# LPC8N04 register map
File version: 0.1
CPU: CM0PLUS r0p0, little endian, no MPU, no FPU, 2 interrupt priority bits
Registers are 32-bit, read-write, no defined reset value unless marked. A register's access mark holds for its fields unless they carry their own. Offsets are from the block's base; [hi:lo] are bit positions.

## FLASH — Flash controller
Base 0x4003C000
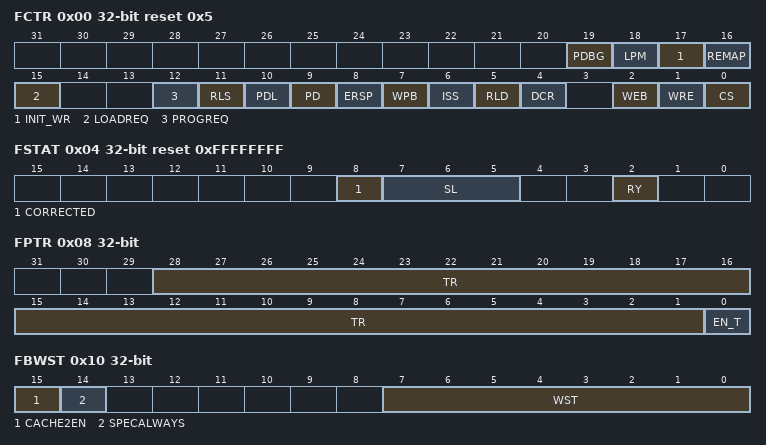
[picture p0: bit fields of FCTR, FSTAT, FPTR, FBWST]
0x00 FCTR reset 0x5 (reset mask 0x0) — Flash Control register
  [19] PDBG — When set, bandgap goes into powerdown mode.
  [18] LPM — When set, the memory goes into low power mode.
  [17] INIT_WR — Writing a ?1? to this field together with reset values for all other fields of the FCTR register starts write initialization. Once set, this bit is only cleared by a controller reset.
  [16] REMAP — When 1, address remapping is enabled
  [15] LOADREQ — When it is written with 1, a memory write operation is triggered. Always reads as 0.
  [12] PROGREQ — At 1 whenever the memory is busy doing program/erase
  [11] RLS — When 1, sector latches are read instead of the memory array.
  [10] PDL — When high, the page register is preset to all 1.
  [9] PD — When high, the memory is forced into power-down mode.
  [8] ERSP — If set, single page erase mode is enabled. The bit is automatically reset at the end of the erase
  [7] WPB — When 1, program/erase is enabled. When 0, read or write is selected, depending on bit WEB
  [6] ISS — When 1, the index sector is accessed instead of the main array. When 0, the MSB of the address bus determines index sector access.
  [5] RLD — When 1, the page register datalatches are read instead of the matrix. Row and sector address bits are not significant
  [4] DCR — When 1, DC Read mode is selected
  [2] WEB — When this bit is cleared, program/erase starts. It is automatically set to 1 at the end of the operation
  [1] WRE — When bit WPB=1, this bit selects between erase (WRE=0) and program (WRE=1). When WPB=0, it selects between read (WRE=0) and write (WRE=1).
  [0] CS — When 0, the device is in standby mode. CS must be 1 for proper operation.
0x04 FSTAT ro reset 0xFFFFFFFF (reset mask 0x0) — Flash status register
  [8] CORRECTED — ECC detected a correctable error
  [7:5] SL — Sector latches: bit 2=selected, 1=locked, 0=protected
  [2] RY — RY=1 whenever the flash is not busy reading, programming or erasing
0x08 FPTR — Flash program-time register
  [28:1] TR — Duration of the program/erase pulse, in timing reference clock cycles.
  [0] EN_T — When set, timer starts. It is automatically cleared when TR reaches 0.
0x10 FBWST — Flash wait state register
  [15] CACHE2EN — When caching is enabled: if this bit is 1, more than a word can be cached; otherwise only the last word read is kept in the cache. When caching is disabled or unavailable, this bit has no effect.
  [14] SPECALWAYS — Speculative reading: (0) single speculative reading; (1) always speculative reading
  [7:0] WST — number of wait states
0x1C FCRA — Flash program clock divider
  [11:0] FCRA — When 0, FCRA clock is stopped. Otherwise, its frequency is the timing reference clock frequency divided by (FCRA+1).
0x20 FMSSTART — Flash checksum start address register
  [16:0] STARTA — Start address for signature generation. The address is in units of memory words, not bytes. Bits 2:0 cannot be written and are forced to 000.
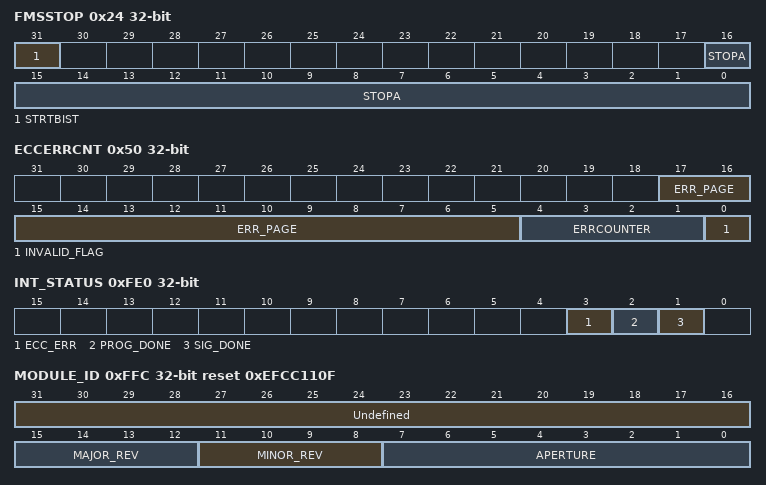
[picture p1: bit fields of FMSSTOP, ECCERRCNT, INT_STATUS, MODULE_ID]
0x24 FMSSTOP — Flash checksum stop address register
  [31] STRTBIST — When this bit is written to 1, signature generation starts. At the end of signature generation, this bit is automatically cleared.
  [16:0] STOPA — Stop address for signature generation (the word specified by STOPA is included in the address range). The address is in units of memory words, not bytes. Bits 2:0 cannot be written and are forced to 111.
0x28 FMS16 ro reset 0xFFFFFFFF (reset mask 0x0) — Flash parity signature register
  [15:0] FMS16 — After signature generation has run, this field contains the parity signature for the specified address range
0x2C FMSW0 ro reset 0xFFFFFFFF (reset mask 0x0) — Flash data signature register
  [31:0] FMSW0 — After signature generation has run, this field contains the data signature for the specified address range
0x50 ECCERRCNT ro — ECC status information
  [17:5] ERR_PAGE — page address of the last location containing an ECC (correctable or uncorrectable) error. Only significant if ERRCOUNTER or INVALID_FLAG are non-zero.
  [4:1] ERRCOUNTER — Incremented when an ECC correction occurs (saturates at 1111). Cleared by writing 1 into ECCRSTERRCNT.
  [0] INVALID_FLAG — Set when an uncorrectable ECC error occurs. Cleared by writing 1 into ECCRSTERRCNT
0x54 ECCRSTERRCNT — Invalid flag and error corrected counter reset
  [0] ECCRSTERRCNT — When set, it clears the ECCERRCNT register. Always reads as 0.
0xFD8 INT_CLR_ENABLE wo — Clear interrupt enable bits
  [31:0] CLR_ENABLE — When a CLR_ENABLE bit is written to 1, the corresponding INT_ENABLE bit is cleared.
0xFDC INT_SET_ENABLE wo — Set interrupt enable bits
  [31:0] SET_ENABLE — When a SET_ENABLE bit is written to 1, the corresponding INT_ENABLE bit is set, unless it is a reserved bit.
0xFE0 INT_STATUS ro — Interrupt status bits
  [3] ECC_ERR — This status bit is set if, during a memory read operation (either a user-requested read, or a speculative read, or reads performed during initialization or during signature generation) a correctable or uncorrectable error is detected by ECC decoding logic.
  [2] PROG_DONE — This status bit is set at the end of a high-voltage operation (burn, erase, combined erase+program)
  [1] SIG_DONE — This status bit is set at the end of signature computation
0xFE4 INT_ENABLE wo — Interrupt enable bits
  [31:0] INT_ENABLE — If an INT_ENABLE bit is set, an interrupt request will be generated of the corresponding INT_STATUS bit is asserted.
0xFE8 INT_CLR_STATUS wo — Clear interrupt status bits
  [31:0] CLR_STATUS — When a CLR_STATUS bit is written to 1, the corresponding INT_STATUS bit is cleared.
0xFEC INT_SET_STATUS wo — Set interrupt status bits
  [31:0] SET_STATUS — When a SET_STATUS bit is written to 1, the corresponding INT_STATUS bit is set, unless it is a reserved bit.
0xFFC MODULE_ID ro reset 0xEFCC110F (reset mask 0x0) — Controller memory module identification
  [31:16] Undefined — Identification number; unique module identifier indicating the module ID of the controller
  [15:12] MAJOR_REV — major revision of module implementation
  [11:8] MINOR_REV — Minor revision of module implementation
  [7:0] APERTURE — The size of the memory encoded as (size/4kByte) -1
